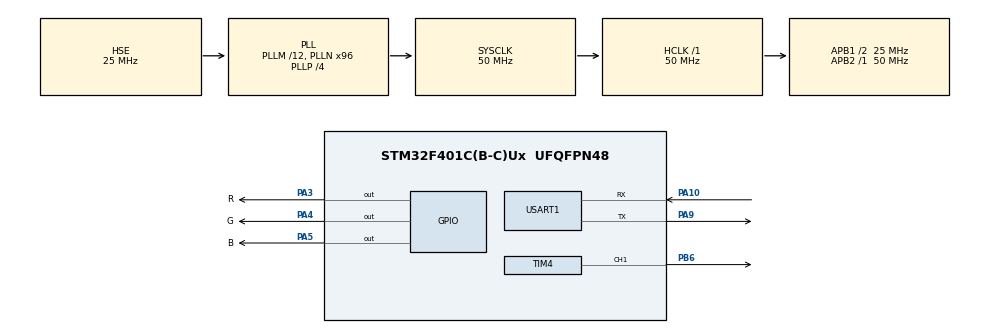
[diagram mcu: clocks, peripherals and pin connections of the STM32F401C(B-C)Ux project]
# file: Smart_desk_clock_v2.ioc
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Dma.Request0=USART1_RX
Dma.Request1=USART1_TX
Dma.USART1_RX.0.Direction=DMA_PERIPH_TO_MEMORY
Dma.USART1_RX.0.FIFOMode=DMA_FIFOMODE_DISABLE
Dma.USART1_RX.0.Instance=DMA2_Stream2
Dma.USART1_RX.0.MemDataAlignment=DMA_MDATAALIGN_BYTE
Dma.USART1_RX.0.MemInc=DMA_MINC_ENABLE
Dma.USART1_RX.0.Mode=DMA_CIRCULAR
Dma.USART1_RX.0.PeriphDataAlignment=DMA_PDATAALIGN_BYTE
Dma.USART1_RX.0.PeriphInc=DMA_PINC_DISABLE
Dma.USART1_RX.0.Priority=DMA_PRIORITY_LOW
Dma.USART1_TX.1.Direction=DMA_MEMORY_TO_PERIPH
Dma.USART1_TX.1.FIFOMode=DMA_FIFOMODE_DISABLE
Dma.USART1_TX.1.Instance=DMA2_Stream7
Dma.USART1_TX.1.MemDataAlignment=DMA_MDATAALIGN_BYTE
Dma.USART1_TX.1.MemInc=DMA_MINC_ENABLE
Dma.USART1_TX.1.Mode=DMA_CIRCULAR
Dma.USART1_TX.1.PeriphDataAlignment=DMA_PDATAALIGN_BYTE
Dma.USART1_TX.1.PeriphInc=DMA_PINC_DISABLE
Dma.USART1_TX.1.Priority=DMA_PRIORITY_LOW
Mcu.Family=STM32F4
Mcu.Name=STM32F401C(B-C)Ux
Mcu.Package=UFQFPN48
NVIC.DMA2_Stream2_IRQn=true\:0\:0\:false\:false\:true\:false\:true
NVIC.DMA2_Stream7_IRQn=true\:0\:0\:false\:false\:true\:false\:true
NVIC.PriorityGroup=NVIC_PRIORITYGROUP_4
NVIC.TIM1_BRK_TIM9_IRQn=true\:0\:0\:false\:false\:true\:true\:true
NVIC.TIM1_TRG_COM_TIM11_IRQn=true\:0\:0\:false\:false\:true\:true\:true
NVIC.TIM3_IRQn=true\:0\:0\:false\:false\:true\:true\:true
NVIC.TIM4_IRQn=true\:0\:0\:false\:false\:true\:true\:true
NVIC.USART1_IRQn=true\:0\:0\:false\:false\:true\:true\:true
PA0-WKUP.Signal=S_TIM2_CH1_ETR
PA10.Mode=Asynchronous
PA10.Signal=USART1_RX
PA13.Mode=Serial_Wire
PA13.Signal=SYS_JTMS-SWDIO
PA14.Mode=Serial_Wire
PA14.Signal=SYS_JTCK-SWCLK
PA3.GPIO_Label=R
PA3.GPIO_PuPd=GPIO_NOPULL
PA3.Signal=GPIO_Output
PA4.GPIO_Label=G
PA4.Signal=GPIO_Output
PA5.GPIO_Label=B
PA5.Signal=GPIO_Output
PA9.Mode=Asynchronous
PA9.Signal=USART1_TX
PB6.Signal=S_TIM4_CH1
PH0\ -\ OSC_IN.Mode=HSE-External-Oscillator
PH0\ -\ OSC_IN.Signal=RCC_OSC_IN
PH1\ -\ OSC_OUT.Mode=HSE-External-Oscillator
PH1\ -\ OSC_OUT.Signal=RCC_OSC_OUT
ProjectManager.HeapSize=0x200
ProjectManager.StackSize=0x400
ProjectManager.TargetToolchain=STM32CubeIDE
RCC.48MHZClocksFreq_Value=50000000
RCC.AHBFreq_Value=50000000
RCC.APB1CLKDivider=RCC_HCLK_DIV2
RCC.APB1Freq_Value=25000000
RCC.APB1TimFreq_Value=50000000
RCC.APB2Freq_Value=50000000
RCC.APB2TimFreq_Value=50000000
RCC.CortexFreq_Value=50000000
RCC.HCLKFreq_Value=50000000
RCC.HSE_VALUE=25000000
RCC.HSI_VALUE=16000000
RCC.LSE_VALUE=32768
RCC.PLLM=12
RCC.PLLN=96
RCC.PLLP=RCC_PLLP_DIV4
RCC.PLLSourceVirtual=RCC_PLLSOURCE_HSE
RCC.SYSCLKFreq_VALUE=50000000
RCC.SYSCLKSource=RCC_SYSCLKSOURCE_PLLCLK
RCC.VCOOutputFreq_Value=200000000
SH.S_TIM2_CH1_ETR.0=TIM2_CH1
SH.S_TIM4_CH1.0=TIM4_CH1,PWM Generation1 CH1
TIM4.Channel-PWM\ Generation1\ CH1=TIM_CHANNEL_1
TIM4.Period=32767
USART1.VirtualMode=VM_ASYNC
VP_TIM11_VS_ClockSourceINT.Mode=Enable_Timer
VP_TIM3_VS_ClockSourceINT.Mode=Internal
VP_TIM4_VS_ClockSourceINT.Mode=Internal
VP_TIM9_VS_ClockSourceINT.Mode=Internal
board=custom

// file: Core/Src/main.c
/* USER CODE BEGIN Header */
/**
  ******************************************************************************
  * @file           : main.c
  * @brief          : Main program body
  ******************************************************************************
  * @attention
  *
  * <h2><center>&copy; Copyright (c) 2023 STMicroelectronics.
  * All rights reserved.</center></h2>
  *
  * This software component is licensed by ST under BSD 3-Clause license,
  * the "License"; You may not use this file except in compliance with the
  * License. You may obtain a copy of the License at:
  *                        opensource.org/licenses/BSD-3-Clause
  *
  ******************************************************************************
  */
/* USER CODE END Header */
#include "main.h"
#include "drv_buzzer.h"

TIM_HandleTypeDef htim3;
TIM_HandleTypeDef htim4;
TIM_HandleTypeDef htim9;
TIM_HandleTypeDef htim11;

UART_HandleTypeDef huart1;
DMA_HandleTypeDef hdma_usart1_rx;
DMA_HandleTypeDef hdma_usart1_tx;

void SystemClock_Config(void);
static void MX_GPIO_Init(void);
static void MX_DMA_Init(void);
static void MX_USART1_UART_Init(void);
static void MX_TIM4_Init(void);
static void MX_TIM3_Init(void);
static void MX_TIM9_Init(void);
static void MX_TIM11_Init(void);

int main(void)
{

  /* MCU Configuration--------------------------------------------------------*/

  /* Reset of all peripherals, Initializes the Flash interface and the Systick. */
  HAL_Init();

  /* Configure the system clock */
  SystemClock_Config();

  /* Initialize all configured peripherals */
  MX_GPIO_Init();
  MX_DMA_Init();
  MX_USART1_UART_Init();
  MX_TIM4_Init();
  MX_TIM3_Init();
  MX_TIM9_Init();
  MX_TIM11_Init();
  /* USER CODE BEGIN 2 */
  drv_buzzer_init();
  drv_buzzer_music(NOKIA_TUNE);
  /* USER CODE END 2 */

  /* Infinite loop */
  while (1)
  {
    bsp_gpio_set_pin(R_GPIO_Port, R_Pin);
    HAL_Delay(200);
    bsp_gpio_reset_pin(R_GPIO_Port, R_Pin);
    HAL_Delay(200);

    bsp_gpio_set_pin(G_GPIO_Port, G_Pin);
    HAL_Delay(200);
    bsp_gpio_reset_pin(G_GPIO_Port, G_Pin);
    HAL_Delay(200);

    bsp_gpio_set_pin(B_GPIO_Port, B_Pin);
    HAL_Delay(200);
    bsp_gpio_reset_pin(B_GPIO_Port, B_Pin);
    HAL_Delay(200);
  }
}

void SystemClock_Config(void)
{
  RCC_OscInitTypeDef RCC_OscInitStruct = {0};
  RCC_ClkInitTypeDef RCC_ClkInitStruct = {0};

  /** Configure the main internal regulator output voltage
  */
  __HAL_RCC_PWR_CLK_ENABLE();
  __HAL_PWR_VOLTAGESCALING_CONFIG(PWR_REGULATOR_VOLTAGE_SCALE2);
  /** Initializes the RCC Oscillators according to the specified parameters
  * in the RCC_OscInitTypeDef structure.
  */
  RCC_OscInitStruct.OscillatorType = RCC_OSCILLATORTYPE_HSE;
  RCC_OscInitStruct.HSEState = RCC_HSE_ON;
  RCC_OscInitStruct.PLL.PLLState = RCC_PLL_ON;
  RCC_OscInitStruct.PLL.PLLSource = RCC_PLLSOURCE_HSE;
  RCC_OscInitStruct.PLL.PLLM = 12;
  RCC_OscInitStruct.PLL.PLLN = 96;
  RCC_OscInitStruct.PLL.PLLP = RCC_PLLP_DIV4;
  RCC_OscInitStruct.PLL.PLLQ = 4;
  if (HAL_RCC_OscConfig(&RCC_OscInitStruct) != HAL_OK)
  {
    Error_Handler();
  }
  /** Initializes the CPU, AHB and APB buses clocks
  */
  RCC_ClkInitStruct.ClockType = RCC_CLOCKTYPE_HCLK|RCC_CLOCKTYPE_SYSCLK
                              |RCC_CLOCKTYPE_PCLK1|RCC_CLOCKTYPE_PCLK2;
  RCC_ClkInitStruct.SYSCLKSource = RCC_SYSCLKSOURCE_PLLCLK;
  RCC_ClkInitStruct.AHBCLKDivider = RCC_SYSCLK_DIV1;
  RCC_ClkInitStruct.APB1CLKDivider = RCC_HCLK_DIV2;
  RCC_ClkInitStruct.APB2CLKDivider = RCC_HCLK_DIV1;

  if (HAL_RCC_ClockConfig(&RCC_ClkInitStruct, FLASH_LATENCY_1) != HAL_OK)
  {
    Error_Handler();
  }
}

static void MX_TIM3_Init(void)
{

  TIM_ClockConfigTypeDef sClockSourceConfig = {0};
  TIM_MasterConfigTypeDef sMasterConfig = {0};

  htim3.Instance = TIM3;
  htim3.Init.Prescaler = 0;
  htim3.Init.CounterMode = TIM_COUNTERMODE_UP;
  htim3.Init.Period = 65535;
  htim3.Init.ClockDivision = TIM_CLOCKDIVISION_DIV1;
  htim3.Init.AutoReloadPreload = TIM_AUTORELOAD_PRELOAD_DISABLE;
  if (HAL_TIM_Base_Init(&htim3) != HAL_OK)
  {
    Error_Handler();
  }
  sClockSourceConfig.ClockSource = TIM_CLOCKSOURCE_INTERNAL;
  if (HAL_TIM_ConfigClockSource(&htim3, &sClockSourceConfig) != HAL_OK)
  {
    Error_Handler();
  }
  sMasterConfig.MasterOutputTrigger = TIM_TRGO_RESET;
  sMasterConfig.MasterSlaveMode = TIM_MASTERSLAVEMODE_DISABLE;
  if (HAL_TIMEx_MasterConfigSynchronization(&htim3, &sMasterConfig) != HAL_OK)
  {
    Error_Handler();
  }

}

static void MX_TIM4_Init(void)
{

  TIM_ClockConfigTypeDef sClockSourceConfig = {0};
  TIM_MasterConfigTypeDef sMasterConfig = {0};
  TIM_OC_InitTypeDef sConfigOC = {0};

  htim4.Instance = TIM4;
  htim4.Init.Prescaler = 0;
  htim4.Init.CounterMode = TIM_COUNTERMODE_UP;
  htim4.Init.Period = 32767;
  htim4.Init.ClockDivision = TIM_CLOCKDIVISION_DIV1;
  htim4.Init.AutoReloadPreload = TIM_AUTORELOAD_PRELOAD_DISABLE;
  if (HAL_TIM_Base_Init(&htim4) != HAL_OK)
  {
    Error_Handler();
  }
  sClockSourceConfig.ClockSource = TIM_CLOCKSOURCE_INTERNAL;
  if (HAL_TIM_ConfigClockSource(&htim4, &sClockSourceConfig) != HAL_OK)
  {
    Error_Handler();
  }
  if (HAL_TIM_PWM_Init(&htim4) != HAL_OK)
  {
    Error_Handler();
  }
  sMasterConfig.MasterOutputTrigger = TIM_TRGO_RESET;
  sMasterConfig.MasterSlaveMode = TIM_MASTERSLAVEMODE_DISABLE;
  if (HAL_TIMEx_MasterConfigSynchronization(&htim4, &sMasterConfig) != HAL_OK)
  {
    Error_Handler();
  }
  sConfigOC.OCMode = TIM_OCMODE_PWM1;
  sConfigOC.Pulse = 0;
  sConfigOC.OCPolarity = TIM_OCPOLARITY_HIGH;
  sConfigOC.OCFastMode = TIM_OCFAST_DISABLE;
  if (HAL_TIM_PWM_ConfigChannel(&htim4, &sConfigOC, TIM_CHANNEL_1) != HAL_OK)
  {
    Error_Handler();
  }
  HAL_TIM_MspPostInit(&htim4);

}

static void MX_TIM9_Init(void)
{

  TIM_ClockConfigTypeDef sClockSourceConfig = {0};

  htim9.Instance = TIM9;
  htim9.Init.Prescaler = 0;
  htim9.Init.CounterMode = TIM_COUNTERMODE_UP;
  htim9.Init.Period = 65535;
  htim9.Init.ClockDivision = TIM_CLOCKDIVISION_DIV1;
  htim9.Init.AutoReloadPreload = TIM_AUTORELOAD_PRELOAD_DISABLE;
  if (HAL_TIM_Base_Init(&htim9) != HAL_OK)
  {
    Error_Handler();
  }
  sClockSourceConfig.ClockSource = TIM_CLOCKSOURCE_INTERNAL;
  if (HAL_TIM_ConfigClockSource(&htim9, &sClockSourceConfig) != HAL_OK)
  {
    Error_Handler();
  }

}

static void MX_TIM11_Init(void)
{

  htim11.Instance = TIM11;
  htim11.Init.Prescaler = 0;
  htim11.Init.CounterMode = TIM_COUNTERMODE_UP;
  htim11.Init.Period = 65535;
  htim11.Init.ClockDivision = TIM_CLOCKDIVISION_DIV1;
  htim11.Init.AutoReloadPreload = TIM_AUTORELOAD_PRELOAD_DISABLE;
  if (HAL_TIM_Base_Init(&htim11) != HAL_OK)
  {
    Error_Handler();
  }

}

static void MX_USART1_UART_Init(void)
{

  huart1.Instance = USART1;
  huart1.Init.BaudRate = 115200;
  huart1.Init.WordLength = UART_WORDLENGTH_8B;
  huart1.Init.StopBits = UART_STOPBITS_1;
  huart1.Init.Parity = UART_PARITY_NONE;
  huart1.Init.Mode = UART_MODE_TX_RX;
  huart1.Init.HwFlowCtl = UART_HWCONTROL_NONE;
  huart1.Init.OverSampling = UART_OVERSAMPLING_16;
  if (HAL_UART_Init(&huart1) != HAL_OK)
  {
    Error_Handler();
  }

}

static void MX_DMA_Init(void)
{

  /* DMA controller clock enable */
  __HAL_RCC_DMA2_CLK_ENABLE();

  /* DMA interrupt init */
  /* DMA2_Stream2_IRQn interrupt configuration */
  HAL_NVIC_SetPriority(DMA2_Stream2_IRQn, 0, 0);
  HAL_NVIC_EnableIRQ(DMA2_Stream2_IRQn);
  /* DMA2_Stream7_IRQn interrupt configuration */
  HAL_NVIC_SetPriority(DMA2_Stream7_IRQn, 0, 0);
  HAL_NVIC_EnableIRQ(DMA2_Stream7_IRQn);

}

static void MX_GPIO_Init(void)
{
  GPIO_InitTypeDef GPIO_InitStruct = {0};

  /* GPIO Ports Clock Enable */
  __HAL_RCC_GPIOH_CLK_ENABLE();
  __HAL_RCC_GPIOA_CLK_ENABLE();
  __HAL_RCC_GPIOB_CLK_ENABLE();

  /*Configure GPIO pin Output Level */
  HAL_GPIO_WritePin(GPIOA, R_Pin|G_Pin|B_Pin, GPIO_PIN_RESET);

  /*Configure GPIO pin : PA0 */
  GPIO_InitStruct.Pin = GPIO_PIN_0;
  GPIO_InitStruct.Mode = GPIO_MODE_AF_PP;
  GPIO_InitStruct.Pull = GPIO_NOPULL;
  GPIO_InitStruct.Speed = GPIO_SPEED_FREQ_LOW;
  GPIO_InitStruct.Alternate = GPIO_AF1_TIM2;
  HAL_GPIO_Init(GPIOA, &GPIO_InitStruct);

  /*Configure GPIO pins : R_Pin G_Pin B_Pin */
  GPIO_InitStruct.Pin = R_Pin|G_Pin|B_Pin;
  GPIO_InitStruct.Mode = GPIO_MODE_OUTPUT_PP;
  GPIO_InitStruct.Pull = GPIO_NOPULL;
  GPIO_InitStruct.Speed = GPIO_SPEED_FREQ_LOW;
  HAL_GPIO_Init(GPIOA, &GPIO_InitStruct);

}

void Error_Handler(void)
{
  __disable_irq();
  while (1)
  {
  }
}

/************************ (C) COPYRIGHT STMicroelectronics *****END OF FILE****/
